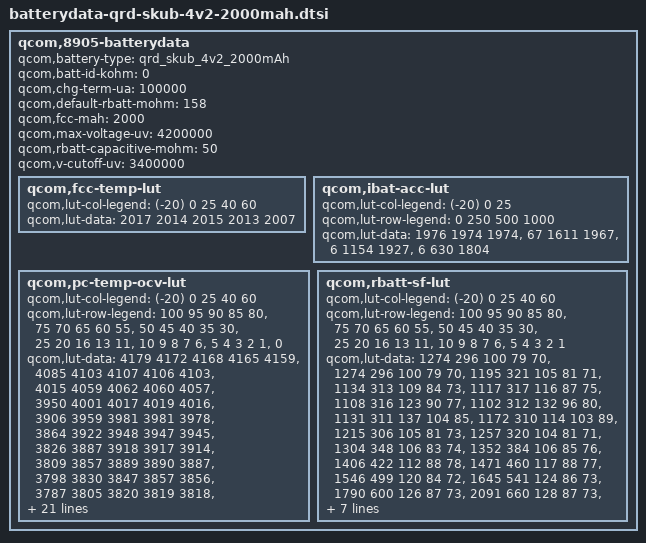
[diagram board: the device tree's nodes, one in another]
/* Copyright (c) 2017, 2020, The Linux Foundation. All rights reserved.
 *
 * This program is free software; you can redistribute it and/or modify
 * it under the terms of the GNU General Public License version 2 and
 * only version 2 as published by the Free Software Foundation.
 *
 * This program is distributed in the hope that it will be useful,
 * but WITHOUT ANY WARRANTY; without even the implied warranty of
 * MERCHANTABILITY or FITNESS FOR A PARTICULAR PURPOSE.  See the
 * GNU General Public License for more details.
 */

qcom,8905-batterydata {
	qcom,battery-type = "qrd_skub_4v2_2000mAh";
	qcom,batt-id-kohm = <0>;
	qcom,chg-term-ua = <100000>;
	qcom,default-rbatt-mohm = <158>;
	qcom,fcc-mah = <2000>;
	qcom,max-voltage-uv = <4200000>;
	qcom,rbatt-capacitive-mohm = <50>;
	qcom,v-cutoff-uv = <3400000>;

	qcom,fcc-temp-lut {
		qcom,lut-col-legend = <(-20) 0 25 40 60>;
		qcom,lut-data = <2017 2014 2015 2013 2007>;
	};

	qcom,ibat-acc-lut {
		qcom,lut-col-legend = <(-20) 0 25>;
		qcom,lut-row-legend = <0 250 500 1000>;
		qcom,lut-data = <1976 1974 1974>,
				<67 1611 1967>,
				<6 1154 1927>,
				<6 630 1804>;
	};

	qcom,pc-temp-ocv-lut {
		qcom,lut-col-legend = <(-20) 0 25 40 60>;
		qcom,lut-row-legend = <100 95 90 85 80>,
					<75 70 65 60 55>,
					<50 45 40 35 30>,
					<25 20 16 13 11>,
					<10 9 8 7 6>,
					<5 4 3 2 1>,
					<0>;
		qcom,lut-data = <4179 4172 4168 4165 4159>,
				<4085 4103 4107 4106 4103>,
				<4015 4059 4062 4060 4057>,
				<3950 4001 4017 4019 4016>,
				<3906 3959 3981 3981 3978>,
				<3864 3922 3948 3947 3945>,
				<3826 3887 3918 3917 3914>,
				<3809 3857 3889 3890 3887>,
				<3798 3830 3847 3857 3856>,
				<3787 3805 3820 3819 3818>,
				<3776 3790 3800 3801 3799>,
				<3766 3780 3787 3787 3785>,
				<3755 3772 3776 3776 3774>,
				<3743 3764 3769 3768 3765>,
				<3732 3754 3762 3758 3751>,
				<3717 3739 3749 3741 3728>,
				<3700 3717 3731 3723 3710>,
				<3680 3702 3707 3700 3688>,
				<3662 3691 3687 3681 3668>,
				<3648 3683 3678 3673 3662>,
				<3639 3678 3676 3671 3661>,
				<3629 3673 3673 3669 3659>,
				<3615 3667 3670 3667 3657>,
				<3600 3659 3666 3663 3652>,
				<3581 3647 3656 3651 3638>,
				<3557 3624 3628 3622 3606>,
				<3525 3587 3582 3575 3558>,
				<3476 3530 3520 3513 3497>,
				<3399 3448 3440 3432 3416>,
				<3271 3320 3319 3311 3292>,
				<3000 3000 3000 3000 3000>;
	};

	qcom,rbatt-sf-lut {
		qcom,lut-col-legend = <(-20) 0 25 40 60>;
		qcom,lut-row-legend = <100 95 90 85 80>,
					<75 70 65 60 55>,
					<50 45 40 35 30>,
					<25 20 16 13 11>,
					<10 9 8 7 6>,
					<5 4 3 2 1>;
		qcom,lut-data = <1274 296 100 79 70>,
				<1274 296 100 79 70>,
				<1195 321 105 81 71>,
				<1134 313 109 84 73>,
				<1117 317 116 87 75>,
				<1108 316 123 90 77>,
				<1102 312 132 96 80>,
				<1131 311 137 104 85>,
				<1172 310 114 103 89>,
				<1215 306 105 81 73>,
				<1257 320 104 81 71>,
				<1304 348 106 83 74>,
				<1352 384 106 85 76>,
				<1406 422 112 88 78>,
				<1471 460 117 88 77>,
				<1546 499 120 84 72>,
				<1645 541 124 86 73>,
				<1790 600 126 87 73>,
				<2091 660 128 87 73>,
				<2167 679 127 86 73>,
				<2329 690 130 87 74>,
				<2623 722 134 89 75>,
				<3022 764 140 93 77>,
				<3564 817 149 96 79>,
				<4335 880 157 98 78>,
				<5564 956 160 97 77>,
				<7560 1065 169 99 79>,
				<11352 1228 192 105 82>,
				<19407 1734 232 116 88>,
				<38753 3324 311 141 104>;
	};
};
